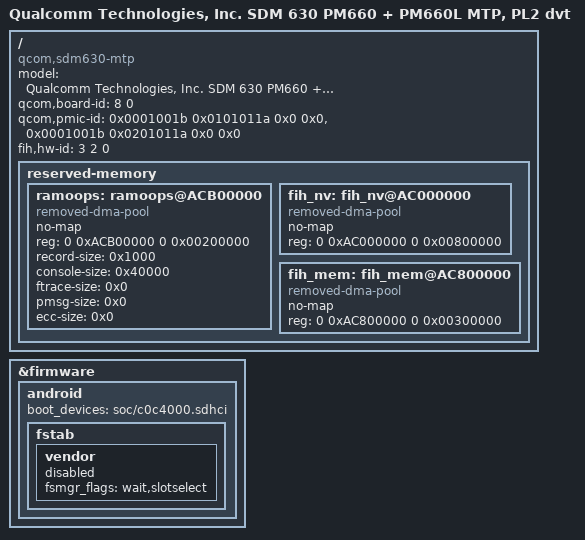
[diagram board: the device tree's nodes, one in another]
/* Copyright (c) 2017, The Linux Foundation. All rights reserved.
 *
 * This program is free software; you can redistribute it and/or modify
 * it under the terms of the GNU General Public License version 2 and
 * only version 2 as published by the Free Software Foundation.
 *
 * This program is distributed in the hope that it will be useful,
 * but WITHOUT ANY WARRANTY; without even the implied warranty of
 * MERCHANTABILITY or FITNESS FOR A PARTICULAR PURPOSE.  See the
 * GNU General Public License for more details.
 */


/dts-v1/;

#include "../qcom/sdm630.dtsi"
#include "../qcom/sdm630-mtp.dtsi"
// #include "sdm660-internal-codec-pl2.dtsi"

/ {
	model = "Qualcomm Technologies, Inc. SDM 630 PM660 + PM660L MTP, PL2 dvt";
	compatible = "qcom,sdm630-mtp", "qcom,sdm630", "qcom,mtp";
	qcom,board-id = <8 0>;
	qcom,pmic-id = <0x0001001b 0x0101011a 0x0 0x0>,
			<0x0001001b 0x0201011a 0x0 0x0>;
	fih,hw-id = <3 2 0>;
};

/ {
	reserved-memory {
		ramoops: ramoops@ACB00000 {
			compatible = "removed-dma-pool", "ramoops";
			no-map;
			reg = <0 0xACB00000 0 0x00200000>;
			record-size = <0x1000>;
			console-size = <0x40000>;
			ftrace-size = <0x0>;
			pmsg-size = <0x0>;
			ecc-size = <0x0>;
			status = "ok";
		};
		fih_nv: fih_nv@AC000000 {
			compatible = "removed-dma-pool";
			no-map;
			reg = <0 0xAC000000 0 0x00800000>;
		};
		fih_mem: fih_mem@AC800000 {
			compatible = "removed-dma-pool";
			no-map;
			reg = <0 0xAC800000 0 0x00300000>;
		};
	};
};

&firmware {
	android {
		boot_devices = "soc/c0c4000.sdhci";
		fstab {
			vendor {
				fsmgr_flags = "wait,slotselect";
				status = "disabled";
			};
		};
	};
};

#include "nokia/display/dsi-panel-fih-ft8716-1080p-video-pl2.dtsi"
